# iqn_aid register map
Vendor: Texas Instruments
Registers are 32-bit, read-only, no defined reset value unless marked. A register's access mark holds for its fields unless they carry their own. Offsets are as the file gives them; [hi:lo] are bit positions; lines under a group give offsets from that group; {n}, {i} and the like mark numbered series; 'fields as' and 'values as' point back to an identical list.

## IQN_AID (part 2 of 2)
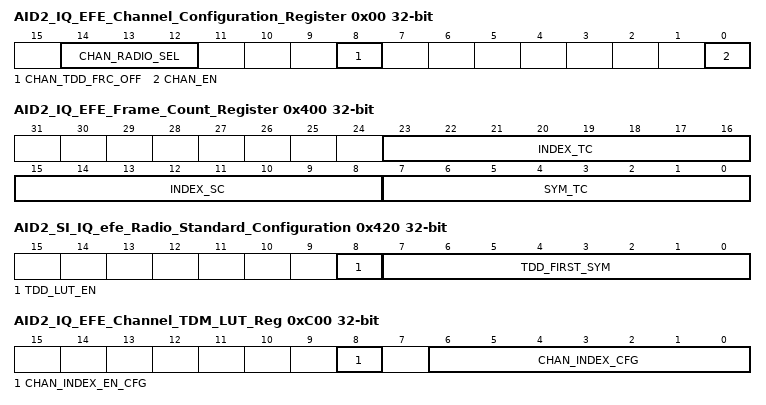
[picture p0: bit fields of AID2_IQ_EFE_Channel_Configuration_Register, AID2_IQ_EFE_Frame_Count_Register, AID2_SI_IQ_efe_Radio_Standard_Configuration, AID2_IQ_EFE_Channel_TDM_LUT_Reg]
0x00 AID2_IQ_EFE_Channel_Configuration_Register rw — (1 of 1, stride 0)
  [14:12] CHAN_RADIO_SEL — Assigns each channel to one of eight radio standard groups. i.e. radio standard 0 may be LTE 20MHz
  [8] CHAN_TDD_FRC_OFF — Alternate TDD mode for controlling TDD also used for GSM Base Band Hopping. APP SW controls updates this bit each symbol of time to control whether the next symbol will be TDD OFF. TDD OFF channels generate no Ingress DMA traffic and expect no Egress DMA
  [0] CHAN_EN — Enable channel
0x200 AID2_IQ_EFE_Configuration_Register rw — (1 of 1, stride 0)
  [0] LOOPBACK_EN — (TI use Only) 0x1: Ingress data from ICC is looped back to Egress data to ICC. DMA traffic is unused. (i.e. for purpose of early DFE only testing)
0x240 AID2_IQ_EFE_Global_Enable_Set_Reg wo — (1 of 1, stride 0)
  [31:0] DONT_CARE — A write of any value to this register which sets (enables) global enable
0x244 AID2_IQ_EFE_Global_Enable_Clear_Reg wo — (1 of 1, stride 0)
  [31:0] DONT_CARE — A write of any value to this register which clears (enables) global enable
0x248 AID2_IQ_EFE_Global_Enable_Status — (1 of 1, stride 0)
  [0] ENABLE — 0x1: efe_ON 0x0:efe_OFF
0x260 AID2_IQ_EFE_Channel_ON_Status_Reg — (1 of 1, stride 0)
  [31:0] CHAN_ON — 0x1: CHAN_ON 0x0:CHAN_OFF
0x280 AID2_IQ_EFE_IN_Packet_Status_Registers — (1 of 1, stride 0)
  [31:0] IN_PKT — 0x1: IN_PKT 0x0:OUT_PKT
0x2A0 AID2_IQ_EFE_DMA_SYNC_Status_Registers — (1 of 1, stride 0)
  [31:0] DMA_SYNC — 0x1: DMA synchronized to radio timing for this channel 0x0:DMA not synchronized to radio timing for this channel. Channel is in in re-sync mode.
0x400 AID2_IQ_EFE_Frame_Count_Register rw — (1 of 1, stride 0)
  [23:16] INDEX_TC — Radio Framing Counter. Index Counter Terminal Count. Index counter terminal count which is the last value of the Index Counter before it wraps. For simple use case, program same as frm_sym_tc.
  [15:8] INDEX_SC — Radio Framing Counter. Index Counter Starting Location. Starting location of the Sample Terminal Count LUT loaded into the Index Counter when it first starts and each time it wraps. Depending on the radio standard, the index will wrap once per radio frame
  [7:0] SYM_TC — Radio Framing Counter. Symbol Count. Number of symbols per frame programmed as a terminal count.
0x420 AID2_SI_IQ_efe_Radio_Standard_Configuration rw — (1 of 1, stride 0)
  [8] TDD_LUT_EN — Enable TDD
  [7:0] TDD_FIRST_SYM — Selects first symbol to start TDD
{0x440+0x20*i} AID2_IQ_efe_Radio_Standard_{i}_TDD_ENABLE_LUT rw (i=0..7) — (1 of 1, stride 0)
  [31:0] TDD_EN — enables/disables DMA of whole symbols (PktDMA packets). Program as 0xffff for most applications.
0x600 AID2_IQ_EFE_Channel_AXC_Offset_Reg rw — (1 of 32, stride 4)
  [19:0] AXC_OFFSET — AxC-by-AxC delay control. Allows different timing alignments for each AxC. DIO, AID applicactions this is a 4 sample offset relatvie to the group or TDM of AxC. AIL CPRI, this is a sample offset relative to the CPRI AxC Group. AIL OBSAI, this is a Radio
0x800 AID2_IQ_EFE_AxC_Framing_Sample_Terminal_Count rw — (1 of 256, stride 4)
  [17:0] SAMP_TC — Radio Framing Counter. Number of samples (4 Bytes) per radio symbol programmed as a terminal count
0xC00 AID2_IQ_EFE_Channel_TDM_LUT_Reg rw — (1 of 256, stride 4)
  [8] CHAN_INDEX_EN_CFG — TDM Channel Index LUT Enable
  [6:0] CHAN_INDEX_CFG — TDM Channel Index
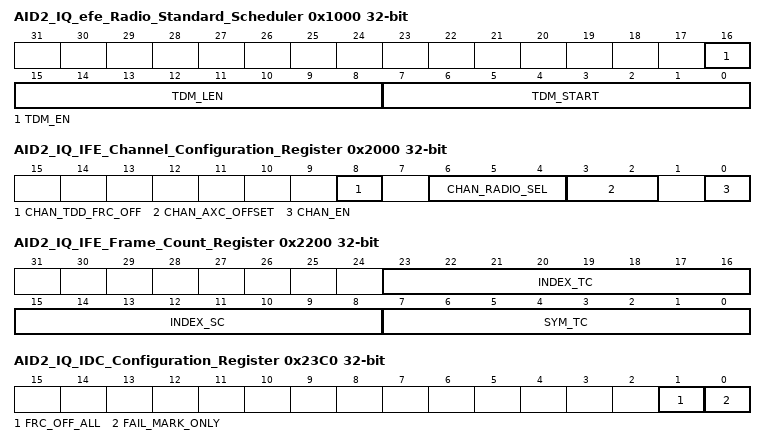
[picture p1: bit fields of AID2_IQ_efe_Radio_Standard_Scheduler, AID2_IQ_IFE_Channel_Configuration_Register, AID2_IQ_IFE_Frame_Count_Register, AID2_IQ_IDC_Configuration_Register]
0x1000 AID2_IQ_efe_Radio_Standard_Scheduler rw — (1 of 1, stride 0)
  [16] TDM_EN — EFE Scheculer Enable TDM
  [15:8] TDM_LEN — EFE Scheduler TDM Length
  [7:0] TDM_START — EFE Scheduler TDM Starting address in LUT
0x2000 AID2_IQ_IFE_Channel_Configuration_Register rw — (1 of 1, stride 0)
  [8] CHAN_TDD_FRC_OFF — Forces a channel into the TDD OFF state on the next symbol after it is set to a 1 regardless of the TDD configuration of the radio standard variant the channel is assigned to.
  [6:4] CHAN_RADIO_SEL — Radio Standard Select
  [3:2] CHAN_AXC_OFFSET — AxC Offset
  [0] CHAN_EN — Enable channel
0x2200 AID2_IQ_IFE_Frame_Count_Register rw — (1 of 1, stride 0)
  [23:16] INDEX_TC — Radio Framing Counter. Index Counter Terminal Count. Index counter terminal count which is the last value of the Index Counter before it wraps. For simple use case, program same as frm_sym_tc.
  [15:8] INDEX_SC — Radio Framing Counter. Index Counter Starting Location. Starting location of the Sample Terminal Count LUT loaded into the Index Counter when it first starts and each time it wraps.
  [7:0] SYM_TC — Radio Framing Counter. Symbol Count. Number of symbols per frame programmed as a terminal count.
0x2220 AID2_IQ_IFE_Radio_Standard_Configuration rw — (1 of 1, stride 0)
  [0] TDD_LUT_EN — Enable TDD
{0x2240+0x20*i} AID2_IQ_IFE_Radio_Standard_{i}_TDD_ENABLE_LUT rw (i=0..7) — (1 of 1, stride 0)
  fields as AID2_IQ_efe_Radio_Standard_0_TDD_ENABLE_LUT
0x2340 AID2_IQ_IFE_Global_Enable_Set_Reg wo — (1 of 1, stride 0)
  fields as AID2_IQ_EFE_Global_Enable_Set_Reg
0x2344 AID2_IQ_IFE_Global_Enable_Clear_Reg wo — (1 of 1, stride 0)
  fields as AID2_IQ_EFE_Global_Enable_Clear_Reg
0x2348 AID2_IQ_IFE_Global_Enable_Status — (1 of 1, stride 0)
  [0] ENABLE — 0x1: ife_ON 0x0:ife_OFF
0x2350 AID2_IQ_IFE_Channel_ON_Status_Reg — (1 of 1, stride 0)
  [31:0] CHAN_ON — 0x1: CHAN_ON 0x0:CHAN_OFF
0x2360 AID2_IQ_IFE_IN_Packet_Status_Registers — (1 of 1, stride 0)
  [31:0] IN_PKT — 0x1: IN_PKT 0x0:OUT_PKT
0x2384 AID2_IQ_IDC_Status_Register — (1 of 1, stride 0)
  [0] EMPTY — Empty indicator for both the PSI Staging FIFO and the CDC FIFO
0x2390 AID2_IQ_IDC_In_Packet_Status_Register — (1 of 1, stride 0)
  [31:0] INPKT — Per-channel in packet status bits where a 0 indicates that the channel is not actively processing a packet and a 1 indicates that it is actively processing a packet. The inpkt to channel assignment is such that inpkt\[0\] is associated with channel 0 and
0x23C0 AID2_IQ_IDC_Configuration_Register rw — (1 of 1, stride 0)
  [1] FRC_OFF_ALL — Forces off all Ingress channels without waiting for an end of symbol or time slot. All open packets are automatically closed by creating an EOP for each open packet
  [0] FAIL_MARK_ONLY — Controls how the IDC handles packet errors detected by IFE
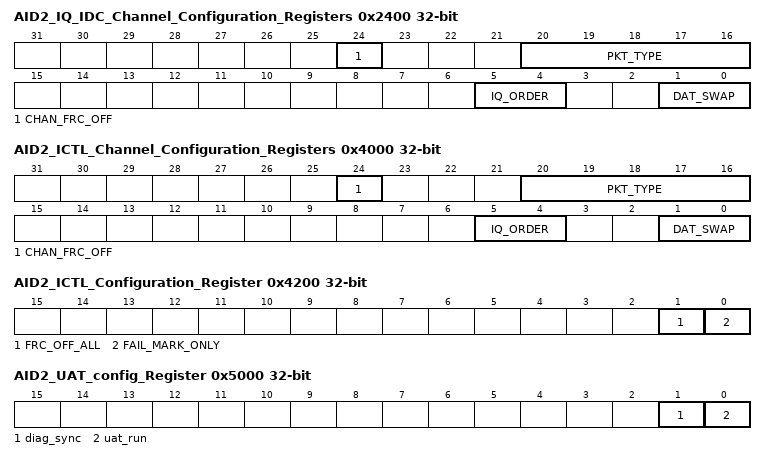
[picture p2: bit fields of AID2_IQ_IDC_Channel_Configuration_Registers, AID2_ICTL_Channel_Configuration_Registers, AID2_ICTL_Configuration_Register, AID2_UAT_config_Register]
0x2400 AID2_IQ_IDC_Channel_Configuration_Registers rw — (1 of 1, stride 0)
  [24] CHAN_FRC_OFF — Forces off all channel without waiting for an end of symbol or time slot. If channel has an open packet it is automatically closed by creating an EOP
  [20:16] PKT_TYPE — Programmable packet type that is inserted into pkt_type field of PKTDMA Info Word 0.
  [5:4] IQ_ORDER — IQ swapping control.
  [1:0] DAT_SWAP — Byte swapping control.
0x2800 AID2_IQ_IFE_AxC_Framing_Sample_Terminal_Count rw — (1 of 256, stride 4)
  fields as AID2_IQ_EFE_AxC_Framing_Sample_Terminal_Count
0x3000 AID2_ECTL_Global_Enable_Set_Reg wo — (1 of 1, stride 0)
  fields as AID2_IQ_EFE_Global_Enable_Set_Reg
0x3004 AID2_ECTL_Global_Enable_Clear_Reg wo — (1 of 1, stride 0)
  fields as AID2_IQ_EFE_Global_Enable_Clear_Reg
0x3008 AID2_ECTL_Global_Enable_Status — (1 of 1, stride 0)
  [0] ENABLE — 0x1: ectl_ON 0x0:ectl_OFF
0x3100 AID2_ECTL_Channel_ON_Status_Reg — (1 of 1, stride 0)
  [15:0] CHAN_ON — 0x1: CHAN_ON 0x0:CHAN_OFF
0x3140 AID2_ECTL_In_Packet_Status_Register — (1 of 1, stride 0)
  [15:0] IN_PKT — Per-channel in packet status bits where a 0 indicates that the channel is not actively processing a packet and a 1 indicates that it is actively processing a packet. The inpkt to channel assignment is such that inpkt\[0\] is associated with channel 0 and
0x3200 AID2_ECTL_Channel_Enable_Configuration_Register rw — (1 of 1, stride 0)
  [0] CHAN_EN — Enable channel
0x3400 AID2_ECTL_DB_Threshold_Register rw — (1 of 1, stride 0)
  [1:0] CHANNEL — Data Buffer Threshold before indicating data available. Per channel
0x4000 AID2_ICTL_Channel_Configuration_Registers rw — (1 of 1, stride 0)
  [24] CHAN_FRC_OFF — Forces off all channel without waiting for an EOP. If channel has an open packet it is automatically closed by creating an EOP
  [20:16] PKT_TYPE — Programmable packet type that is inserted into pkt_type field of PKTDMA Info Word 0.
  [5:4] IQ_ORDER — IQ swapping control.
  [1:0] DAT_SWAP — Byte swapping control.
0x4200 AID2_ICTL_Configuration_Register rw — (1 of 1, stride 0)
  [1] FRC_OFF_ALL — Forces off all Ingress channels without waiting for an EOP. All open packets are automatically closed by creating an EOP for each open packet
  [0] FAIL_MARK_ONLY — Controls how the ICTL handles packet errors detected by ICTL
0x4204 AID2_ICTL_Status_Register — (1 of 1, stride 0)
  fields as AID2_IQ_IDC_Status_Register
0x4210 AID2_ICTL_In_Packet_Status_Register — (1 of 1, stride 0)
  fields as AID2_ECTL_In_Packet_Status_Register
0x4280 AID2_ICTL_Global_Enable_Set_Reg wo — (1 of 1, stride 0)
  fields as AID2_IQ_EFE_Global_Enable_Set_Reg
0x4284 AID2_ICTL_Global_Enable_Clear_Reg wo — (1 of 1, stride 0)
  fields as AID2_IQ_EFE_Global_Enable_Clear_Reg
0x4288 AID2_ICTL_Global_Enable_Status — (1 of 1, stride 0)
  [0] ENABLE — 0x1: ictl_ON 0x0:ictl_OFF
0x42A0 AID2_ICTL_Channel_ON_Status_Reg — (1 of 1, stride 0)
  [15:0] CHAN_ON — 0x1: CHAN_ON 0x0:CHAN_OFF
0x4400 AID2_ICTL_Channel_Enable_Configuration_Register rw — (1 of 1, stride 0)
  [0] CHAN_EN — Enable channel
0x5000 AID2_UAT_config_Register rw — (1 of 1, stride 0)
  [1] diag_sync — diag_sync = 1 starts the BCN and RAD counters if uat_run is set and an AT sync is received. This is only used in simulation and for diagnostics
  [0] uat_run — UAT run starts the BCN and RAD counters free running
0x5004 AID2_UAT_BCN_terminal_count_Register rw — (1 of 1, stride 0)
  [24:0] val — UAT BCN terminal count. BCN counts from zero to this limit and wraps to zero. Program as 2,457,599 for sys_clk=245.76MHz and 3,071,999 for sys_clk=307.2MHz
0x5008 AID2_UAT_BCN_offset_Register rw — (1 of 1, stride 0)
  [24:0] val — Offset correction to the raw uAT BCN counter. Used to correct the alignment of the local uAT BCN to the master AT2 BCN. BCN is initially randomly started. SW uses uat_sync_bcn_capture_sts rd_val to calculate offset correction factor. This correction
0x500C AID2_UAT_SYNC_BCN_capture_Register — (1 of 1, stride 0)
  [24:0] rd_val — uAT raw BCN value captured each frame boundary of AT2 master BCN. Used to calculate uAT BCN offset value for the purpose of aligning uAT to AT2 BCN.
0x5080 AID2_UAT_RADT_terminal_count_Register rw — (1 of 8, stride 16)
  [24:0] val — UAT RADT terminal count. (i.e. 2,457,599 for WCDMA with sys_clk=245.76MHz)
0x5084 AID2_UAT_RADT_offset_Register rw — (1 of 8, stride 16)
  [24:0] val — UAT RADT offset. Value which is added to the raw RADT as a timing correction. RadT is initially randomly started, SW uses radt_capture value to calculate offset correction factor. This correction factor will be Frame size
0x5088 AID2_UAT_SYNC_RADT_capture_Register — (1 of 8, stride 16)
  [24:0] rd_val — UAT RADT sync capture captures the offset RADT count when a uat_mst_slv_sync from the AT occurs. Used by SW to determine correct RADT offset to apply.
0x5100 AID2_UAT_RADT_terminal_count_Register rw — (1 of 8, stride 16)
  fields as AID2_UAT_RADT_terminal_count_Register
0x5104 AID2_UAT_RADT_offset_Register rw — (1 of 8, stride 16)
  fields as AID2_UAT_RADT_offset_Register
0x5108 AID2_UAT_SYNC_RADT_capture_Register — (1 of 8, stride 16)
  fields as AID2_UAT_SYNC_RADT_capture_Register
0x5200 AID2_UAT_RADT_event_compare_Register rw — (1 of 22, stride 8)
  [24:0] val — UAT RADT event compare per RADT. When compare value equals RADT count, frame rate event is generated. Also periodic event (i.e. 4SAMP) is started. The 0 to 7 are for si egress, 8 to 15 for si ingress, 16 to 18 for dio egress, 19 to 21 for dio ingress
0x5204 AID2_UAT_RADT_event_clock_count_tc_Register rw — (1 of 22, stride 8)
  [15:0] val — UAT RADT event clock counter terminal count controls spacing of the periodic strobe (i.e. 4SAMP). Once the uat_evt_radt_cmp_cfg equals the RADT, the period strobe will fire and re-fire every time a clock counter reaches this terminal count. The The 0 to 7
0x8000 AID2_IQ_EDC_Configuration_Register rw — (1 of 1, stride 0)
  [0] PSI_ERR_CHK_DISABLE — Controls how the EDC handles packet errors detected by efe
0x8004 AID2_IQ_EDC_SOP_Counter_Status_Register — (1 of 1, stride 0)
  [23:0] SOP_CNT — Count of the number of SOPs seen by the IQ EDC
0x8008 AID2_IQ_EDC_EOP_Counter_Status_Register — (1 of 1, stride 0)
  [23:0] EOP_CNT — Count of the number of EOPs seen by the IQ EDC
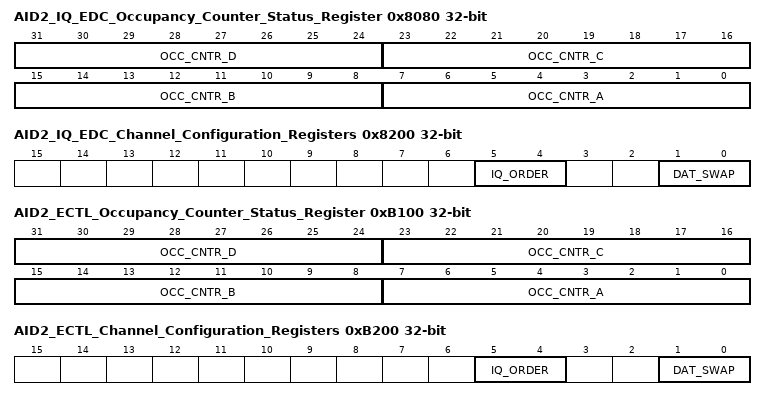
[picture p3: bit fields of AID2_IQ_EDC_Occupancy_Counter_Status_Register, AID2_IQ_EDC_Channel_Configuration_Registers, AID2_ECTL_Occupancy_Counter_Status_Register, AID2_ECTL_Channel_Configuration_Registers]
0x8080 AID2_IQ_EDC_Occupancy_Counter_Status_Register — (1 of 1, stride 0)
  [31:24] OCC_CNTR_D — Occupancy Counter for register D for this address
  [23:16] OCC_CNTR_C — Occupancy Counter for register C for this address
  [15:8] OCC_CNTR_B — Occupancy Counter for register B for this address
  [7:0] OCC_CNTR_A — Occupancy Counter for register A for this address
0x8200 AID2_IQ_EDC_Channel_Configuration_Registers rw — (1 of 1, stride 0)
  [5:4] IQ_ORDER — IQ swapping control.
  [1:0] DAT_SWAP — Byte swapping control.
0xA000 AID2_IQ_IDC_Rate_Control_Configuration_Register rw — (1 of 1, stride 0)
  [3:0] RATE — Rate Controller will allow the IDC to create RATE+1 active requests on the PSI bus within a 32 clock cycle window. As an example, a value of 7 will allow the IDC to create 8 active requests within a 32-clock cycle window which uses 25% of the PSI bus.
0xA004 AID2_IQ_IDC_SOP_Counter_Register — (1 of 1, stride 0)
  [23:0] SOP_CNT — Wrapping count of SOPs sent on PSI.
0xA008 AID2_IQ_IDC_EOP_Counter_Register — (1 of 1, stride 0)
  [23:0] EOP_CNT — Wrapping count of EOPs sent on PSI.
0xB000 AID2_ECTL_Rate_Control_Configuration_Register rw — (1 of 1, stride 0)
  [3:0] RATE — Rate Controller will allow the ECTL to create RATE+1 active requests on the PSI bus within a 16 clock cycle window. As an example, a value of 7 will allow the ICTL to create 8 active requests within a 16-clock cycle window which uses 50% of the PSI bus.
0xB004 AID2_ECTL_SOP_Counter_Status_Register — (1 of 1, stride 0)
  [23:0] SOP_CNT — Count of the number of SOPs seen by the ECTL
0xB008 AID2_ECTL_EOP_Counter_Status_Register — (1 of 1, stride 0)
  [23:0] EOP_CNT — Count of the number of EOPs seen by the ECTL
0xB100 AID2_ECTL_Occupancy_Counter_Status_Register — (1 of 1, stride 0)
  fields as AID2_IQ_EDC_Occupancy_Counter_Status_Register
0xB200 AID2_ECTL_Channel_Configuration_Registers rw — (1 of 1, stride 0)
  fields as AID2_IQ_EDC_Channel_Configuration_Registers
0xC000 AID2_ICTL_Rate_Control_Configuration_Register rw — (1 of 1, stride 0)
  [3:0] RATE — Rate Controller will allow the ICTL to create RATE+1 active requests on the PSI bus within a 16 clock cycle window. As an example, a value of 7 will allow the ICTL to create 8 active requests within a 16-clock cycle window which uses 50% of the PSI bus.
0xC004 AID2_ICTL_SOP_Counter_Register — (1 of 1, stride 0)
  [23:0] SOP_CNT — Wrapping count of SOPs sent on PSI.
0xC008 AID2_ICTL_EOP_Counter_Register — (1 of 1, stride 0)
  [23:0] EOP_CNT — Wrapping count of EOPs sent on PSI.
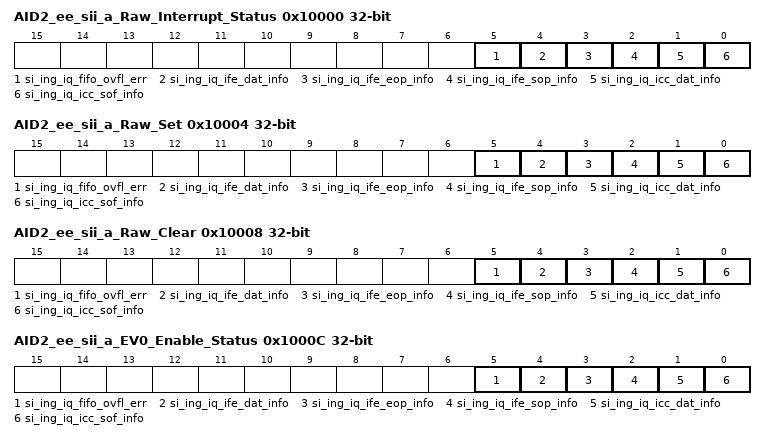
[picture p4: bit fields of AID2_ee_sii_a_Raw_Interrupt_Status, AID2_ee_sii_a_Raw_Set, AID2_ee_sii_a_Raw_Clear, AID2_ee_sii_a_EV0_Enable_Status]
0x10000 AID2_ee_sii_a_Raw_Interrupt_Status — (1 of 1, stride 0)
  [5] si_ing_iq_fifo_ovfl_err — SI Ingress IQ FIFO overflow error
  [4] si_ing_iq_ife_dat_info — SI Ingress IQ IFE transmitted valid data phase
  [3] si_ing_iq_ife_eop_info — SI Ingress IQ IFE transmitted EOP
  [2] si_ing_iq_ife_sop_info — SI Ingress IQ IFE transmitted SOP
  [1] si_ing_iq_icc_dat_info — SI Ingress IQ ICC data transfer received
  [0] si_ing_iq_icc_sof_info — SI Ingress IQ ICC Start of Frame received
0x10004 AID2_ee_sii_a_Raw_Set wo — (1 of 1, stride 0)
  [5] si_ing_iq_fifo_ovfl_err — Sets the corresponding bit in the raw_status register when set. Write only, self-clears.
  [4] si_ing_iq_ife_dat_info — Sets the corresponding bit in the raw_status register when set. Write only, self-clears.
  [3] si_ing_iq_ife_eop_info — Sets the corresponding bit in the raw_status register when set. Write only, self-clears.
  [2] si_ing_iq_ife_sop_info — Sets the corresponding bit in the raw_status register when set. Write only, self-clears.
  [1] si_ing_iq_icc_dat_info — Sets the corresponding bit in the raw_status register when set. Write only, self-clears.
  [0] si_ing_iq_icc_sof_info — Sets the corresponding bit in the raw_status register when set. Write only, self-clears.
0x10008 AID2_ee_sii_a_Raw_Clear wo — (1 of 1, stride 0)
  [5] si_ing_iq_fifo_ovfl_err — Clears the corresponding bit in the raw_status register when set. Write only, self-clears.
  [4] si_ing_iq_ife_dat_info — Clears the corresponding bit in the raw_status register when set. Write only, self-clears.
  [3] si_ing_iq_ife_eop_info — Clears the corresponding bit in the raw_status register when set. Write only, self-clears.
  [2] si_ing_iq_ife_sop_info — Clears the corresponding bit in the raw_status register when set. Write only, self-clears.
  [1] si_ing_iq_icc_dat_info — Clears the corresponding bit in the raw_status register when set. Write only, self-clears.
  [0] si_ing_iq_icc_sof_info — Clears the corresponding bit in the raw_status register when set. Write only, self-clears.
0x1000C AID2_ee_sii_a_EV0_Enable_Status — (1 of 1, stride 0)
  [5] si_ing_iq_fifo_ovfl_err — When set allows the corresponding bit in the raw_status register to generate the intr_sts interrupt. Read only.
  [4] si_ing_iq_ife_dat_info — When set allows the corresponding bit in the raw_status register to generate the intr_sts interrupt. Read only.
  [3] si_ing_iq_ife_eop_info — When set allows the corresponding bit in the raw_status register to generate the intr_sts interrupt. Read only.
  [2] si_ing_iq_ife_sop_info — When set allows the corresponding bit in the raw_status register to generate the intr_sts interrupt. Read only.
  [1] si_ing_iq_icc_dat_info — When set allows the corresponding bit in the raw_status register to generate the intr_sts interrupt. Read only.
  [0] si_ing_iq_icc_sof_info — When set allows the corresponding bit in the raw_status register to generate the intr_sts interrupt. Read only.
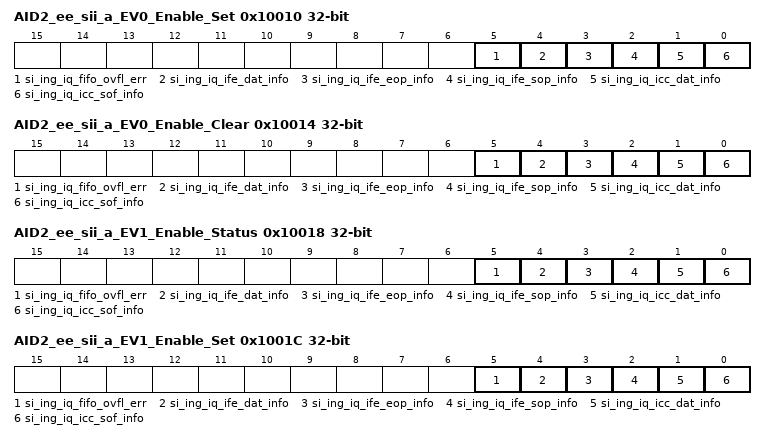
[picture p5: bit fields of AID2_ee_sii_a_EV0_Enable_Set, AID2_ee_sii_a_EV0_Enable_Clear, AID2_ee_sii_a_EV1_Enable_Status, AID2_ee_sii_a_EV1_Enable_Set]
0x10010 AID2_ee_sii_a_EV0_Enable_Set wo — (1 of 1, stride 0)
  [5] si_ing_iq_fifo_ovfl_err — Sets the corresponding bit in the enable register when set. Write only, self-clears.
  [4] si_ing_iq_ife_dat_info — Sets the corresponding bit in the enable register when set. Write only, self-clears.
  [3] si_ing_iq_ife_eop_info — Sets the corresponding bit in the enable register when set. Write only, self-clears.
  [2] si_ing_iq_ife_sop_info — Sets the corresponding bit in the enable register when set. Write only, self-clears.
  [1] si_ing_iq_icc_dat_info — Sets the corresponding bit in the enable register when set. Write only, self-clears.
  [0] si_ing_iq_icc_sof_info — Sets the corresponding bit in the enable register when set. Write only, self-clears.
0x10014 AID2_ee_sii_a_EV0_Enable_Clear wo — (1 of 1, stride 0)
  [5] si_ing_iq_fifo_ovfl_err — Clears the corresponding bit in the enable register when set. Write only, self-clears.
  [4] si_ing_iq_ife_dat_info — Clears the corresponding bit in the enable register when set. Write only, self-clears.
  [3] si_ing_iq_ife_eop_info — Clears the corresponding bit in the enable register when set. Write only, self-clears.
  [2] si_ing_iq_ife_sop_info — Clears the corresponding bit in the enable register when set. Write only, self-clears.
  [1] si_ing_iq_icc_dat_info — Clears the corresponding bit in the enable register when set. Write only, self-clears.
  [0] si_ing_iq_icc_sof_info — Clears the corresponding bit in the enable register when set. Write only, self-clears.
0x10018 AID2_ee_sii_a_EV1_Enable_Status — (1 of 1, stride 0)
  [5] si_ing_iq_fifo_ovfl_err — When set allows the corresponding bit in the raw_status register to generate the intr1_sts interrupt. Read only.
  [4] si_ing_iq_ife_dat_info — When set allows the corresponding bit in the raw_status register to generate the intr1_sts interrupt. Read only.
  [3] si_ing_iq_ife_eop_info — When set allows the corresponding bit in the raw_status register to generate the intr1_sts interrupt. Read only.
  [2] si_ing_iq_ife_sop_info — When set allows the corresponding bit in the raw_status register to generate the intr1_sts interrupt. Read only.
  [1] si_ing_iq_icc_dat_info — When set allows the corresponding bit in the raw_status register to generate the intr1_sts interrupt. Read only.
  [0] si_ing_iq_icc_sof_info — When set allows the corresponding bit in the raw_status register to generate the intr1_sts interrupt. Read only.
0x1001C AID2_ee_sii_a_EV1_Enable_Set wo — (1 of 1, stride 0)
  [5] si_ing_iq_fifo_ovfl_err — Sets the corresponding bit in the intr1_status register when set. Write only, self-clears.
  [4] si_ing_iq_ife_dat_info — Sets the corresponding bit in the intr1_status register when set. Write only, self-clears.
  [3] si_ing_iq_ife_eop_info — Sets the corresponding bit in the intr1_status register when set. Write only, self-clears.
  [2] si_ing_iq_ife_sop_info — Sets the corresponding bit in the intr1_status register when set. Write only, self-clears.
  [1] si_ing_iq_icc_dat_info — Sets the corresponding bit in the intr1_status register when set. Write only, self-clears.
  [0] si_ing_iq_icc_sof_info — Sets the corresponding bit in the intr1_status register when set. Write only, self-clears.
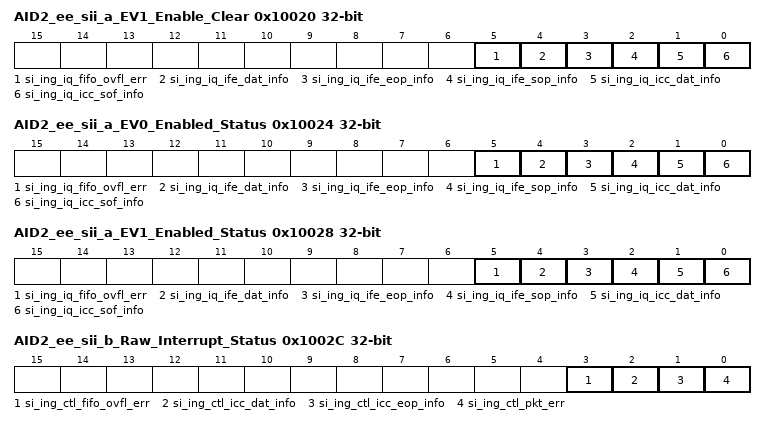
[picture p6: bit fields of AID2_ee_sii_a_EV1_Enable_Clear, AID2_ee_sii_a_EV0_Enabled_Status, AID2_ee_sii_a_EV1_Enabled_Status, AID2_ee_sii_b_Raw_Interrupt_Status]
0x10020 AID2_ee_sii_a_EV1_Enable_Clear wo — (1 of 1, stride 0)
  [5] si_ing_iq_fifo_ovfl_err — Clears the corresponding bit in the intr1_status register when set. Write only, self-clears.
  [4] si_ing_iq_ife_dat_info — Clears the corresponding bit in the intr1_status register when set. Write only, self-clears.
  [3] si_ing_iq_ife_eop_info — Clears the corresponding bit in the intr1_status register when set. Write only, self-clears.
  [2] si_ing_iq_ife_sop_info — Clears the corresponding bit in the intr1_status register when set. Write only, self-clears.
  [1] si_ing_iq_icc_dat_info — Clears the corresponding bit in the intr1_status register when set. Write only, self-clears.
  [0] si_ing_iq_icc_sof_info — Clears the corresponding bit in the intr1_status register when set. Write only, self-clears.
0x10024 AID2_ee_sii_a_EV0_Enabled_Status — (1 of 1, stride 0)
  [5] si_ing_iq_fifo_ovfl_err — AND-ed raw_status bits with the corresponding bit in the enable_status register. Read only.
  [4] si_ing_iq_ife_dat_info — AND-ed raw_status bits with the corresponding bit in the enable_status register. Read only.
  [3] si_ing_iq_ife_eop_info — AND-ed raw_status bits with the corresponding bit in the enable_status register. Read only.
  [2] si_ing_iq_ife_sop_info — AND-ed raw_status bits with the corresponding bit in the enable_status register. Read only.
  [1] si_ing_iq_icc_dat_info — AND-ed raw_status bits with the corresponding bit in the enable_status register. Read only.
  [0] si_ing_iq_icc_sof_info — AND-ed raw_status bits with the corresponding bit in the enable_status register. Read only.
0x10028 AID2_ee_sii_a_EV1_Enabled_Status — (1 of 1, stride 0)
  [5] si_ing_iq_fifo_ovfl_err — AND-ed raw_status bits with the corresponding bit in the intr1_status register. Read only.
  [4] si_ing_iq_ife_dat_info — AND-ed raw_status bits with the corresponding bit in the intr1_status register. Read only.
  [3] si_ing_iq_ife_eop_info — AND-ed raw_status bits with the corresponding bit in the intr1_status register. Read only.
  [2] si_ing_iq_ife_sop_info — AND-ed raw_status bits with the corresponding bit in the intr1_status register. Read only.
  [1] si_ing_iq_icc_dat_info — AND-ed raw_status bits with the corresponding bit in the intr1_status register. Read only.
  [0] si_ing_iq_icc_sof_info — AND-ed raw_status bits with the corresponding bit in the intr1_status register. Read only.
0x1002C AID2_ee_sii_b_Raw_Interrupt_Status — (1 of 1, stride 0)
  [3] si_ing_ctl_fifo_ovfl_err — SI Ingress CTL FIFO overflow error
  [2] si_ing_ctl_icc_dat_info — SI Ingress CTL received valid data phase from ICC
  [1] si_ing_ctl_icc_eop_info — SI Ingress CTL received EOP from ICC
  [0] si_ing_ctl_pkt_err — SI Ingress CTL Packet error occurred
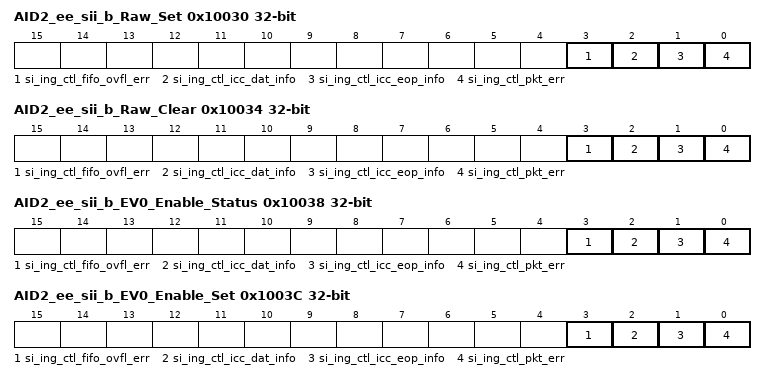
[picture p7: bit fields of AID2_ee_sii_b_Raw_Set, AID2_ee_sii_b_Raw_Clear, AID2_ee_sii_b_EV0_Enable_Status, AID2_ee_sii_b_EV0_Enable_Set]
0x10030 AID2_ee_sii_b_Raw_Set wo — (1 of 1, stride 0)
  [3] si_ing_ctl_fifo_ovfl_err — Sets the corresponding bit in the raw_status register when set. Write only, self-clears.
  [2] si_ing_ctl_icc_dat_info — Sets the corresponding bit in the raw_status register when set. Write only, self-clears.
  [1] si_ing_ctl_icc_eop_info — Sets the corresponding bit in the raw_status register when set. Write only, self-clears.
  [0] si_ing_ctl_pkt_err — Sets the corresponding bit in the raw_status register when set. Write only, self-clears.
0x10034 AID2_ee_sii_b_Raw_Clear wo — (1 of 1, stride 0)
  [3] si_ing_ctl_fifo_ovfl_err — Clears the corresponding bit in the raw_status register when set. Write only, self-clears.
  [2] si_ing_ctl_icc_dat_info — Clears the corresponding bit in the raw_status register when set. Write only, self-clears.
  [1] si_ing_ctl_icc_eop_info — Clears the corresponding bit in the raw_status register when set. Write only, self-clears.
  [0] si_ing_ctl_pkt_err — Clears the corresponding bit in the raw_status register when set. Write only, self-clears.
0x10038 AID2_ee_sii_b_EV0_Enable_Status — (1 of 1, stride 0)
  [3] si_ing_ctl_fifo_ovfl_err — When set allows the corresponding bit in the raw_status register to generate the intr_sts interrupt. Read only.
  [2] si_ing_ctl_icc_dat_info — When set allows the corresponding bit in the raw_status register to generate the intr_sts interrupt. Read only.
  [1] si_ing_ctl_icc_eop_info — When set allows the corresponding bit in the raw_status register to generate the intr_sts interrupt. Read only.
  [0] si_ing_ctl_pkt_err — When set allows the corresponding bit in the raw_status register to generate the intr_sts interrupt. Read only.
0x1003C AID2_ee_sii_b_EV0_Enable_Set wo — (1 of 1, stride 0)
  [3] si_ing_ctl_fifo_ovfl_err — Sets the corresponding bit in the enable register when set. Write only, self-clears.
  [2] si_ing_ctl_icc_dat_info — Sets the corresponding bit in the enable register when set. Write only, self-clears.
  [1] si_ing_ctl_icc_eop_info — Sets the corresponding bit in the enable register when set. Write only, self-clears.
  [0] si_ing_ctl_pkt_err — Sets the corresponding bit in the enable register when set. Write only, self-clears.
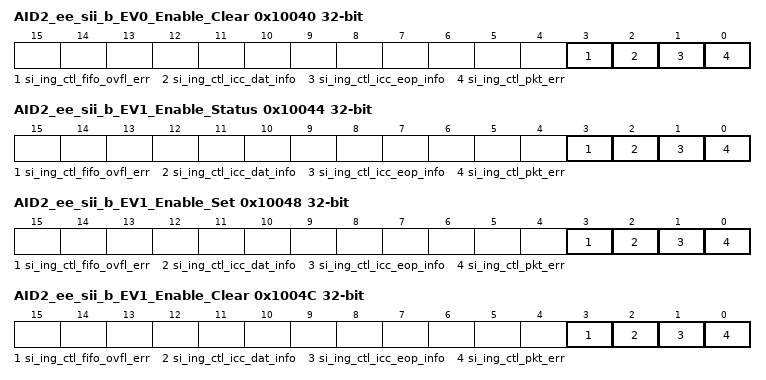
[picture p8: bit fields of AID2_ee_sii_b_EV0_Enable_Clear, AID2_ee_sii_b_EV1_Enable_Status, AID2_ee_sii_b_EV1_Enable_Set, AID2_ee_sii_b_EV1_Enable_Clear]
0x10040 AID2_ee_sii_b_EV0_Enable_Clear wo — (1 of 1, stride 0)
  [3] si_ing_ctl_fifo_ovfl_err — Clears the corresponding bit in the enable register when set. Write only, self-clears.
  [2] si_ing_ctl_icc_dat_info — Clears the corresponding bit in the enable register when set. Write only, self-clears.
  [1] si_ing_ctl_icc_eop_info — Clears the corresponding bit in the enable register when set. Write only, self-clears.
  [0] si_ing_ctl_pkt_err — Clears the corresponding bit in the enable register when set. Write only, self-clears.
0x10044 AID2_ee_sii_b_EV1_Enable_Status — (1 of 1, stride 0)
  [3] si_ing_ctl_fifo_ovfl_err — When set allows the corresponding bit in the raw_status register to generate the intr1_sts interrupt. Read only.
  [2] si_ing_ctl_icc_dat_info — When set allows the corresponding bit in the raw_status register to generate the intr1_sts interrupt. Read only.
  [1] si_ing_ctl_icc_eop_info — When set allows the corresponding bit in the raw_status register to generate the intr1_sts interrupt. Read only.
  [0] si_ing_ctl_pkt_err — When set allows the corresponding bit in the raw_status register to generate the intr1_sts interrupt. Read only.
0x10048 AID2_ee_sii_b_EV1_Enable_Set wo — (1 of 1, stride 0)
  [3] si_ing_ctl_fifo_ovfl_err — Sets the corresponding bit in the intr1_status register when set. Write only, self-clears.
  [2] si_ing_ctl_icc_dat_info — Sets the corresponding bit in the intr1_status register when set. Write only, self-clears.
  [1] si_ing_ctl_icc_eop_info — Sets the corresponding bit in the intr1_status register when set. Write only, self-clears.
  [0] si_ing_ctl_pkt_err — Sets the corresponding bit in the intr1_status register when set. Write only, self-clears.
0x1004C AID2_ee_sii_b_EV1_Enable_Clear wo — (1 of 1, stride 0)
  [3] si_ing_ctl_fifo_ovfl_err — Clears the corresponding bit in the intr1_status register when set. Write only, self-clears.
  [2] si_ing_ctl_icc_dat_info — Clears the corresponding bit in the intr1_status register when set. Write only, self-clears.
  [1] si_ing_ctl_icc_eop_info — Clears the corresponding bit in the intr1_status register when set. Write only, self-clears.
  [0] si_ing_ctl_pkt_err — Clears the corresponding bit in the intr1_status register when set. Write only, self-clears.
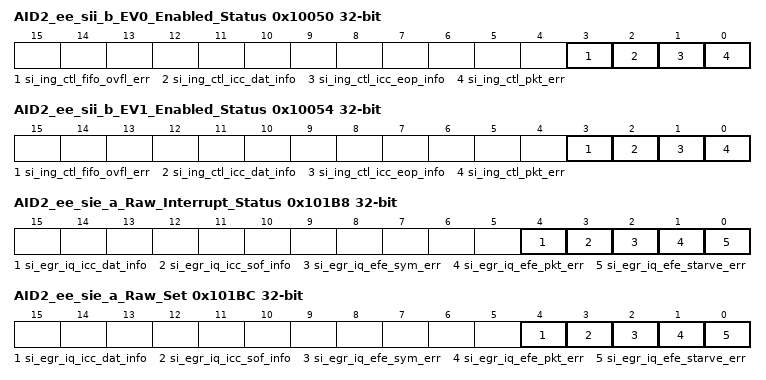
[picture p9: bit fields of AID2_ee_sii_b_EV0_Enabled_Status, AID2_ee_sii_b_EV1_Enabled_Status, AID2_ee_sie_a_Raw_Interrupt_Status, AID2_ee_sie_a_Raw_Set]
0x10050 AID2_ee_sii_b_EV0_Enabled_Status — (1 of 1, stride 0)
  [3] si_ing_ctl_fifo_ovfl_err — AND-ed raw_status bits with the corresponding bit in the enable_status register. Read only.
  [2] si_ing_ctl_icc_dat_info — AND-ed raw_status bits with the corresponding bit in the enable_status register. Read only.
  [1] si_ing_ctl_icc_eop_info — AND-ed raw_status bits with the corresponding bit in the enable_status register. Read only.
  [0] si_ing_ctl_pkt_err — AND-ed raw_status bits with the corresponding bit in the enable_status register. Read only.
0x10054 AID2_ee_sii_b_EV1_Enabled_Status — (1 of 1, stride 0)
  [3] si_ing_ctl_fifo_ovfl_err — AND-ed raw_status bits with the corresponding bit in the intr1_status register. Read only.
  [2] si_ing_ctl_icc_dat_info — AND-ed raw_status bits with the corresponding bit in the intr1_status register. Read only.
  [1] si_ing_ctl_icc_eop_info — AND-ed raw_status bits with the corresponding bit in the intr1_status register. Read only.
  [0] si_ing_ctl_pkt_err — AND-ed raw_status bits with the corresponding bit in the intr1_status register. Read only.
0x10058 AID2_ee_sii_c_Raw_Interrupt_Status — (1 of 1, stride 0)
  [31:0] si_ing_iq_sof_err — SI Ingress IQ per channel Start of Frame alignment error
0x1005C AID2_ee_sii_c_Raw_Set wo — (1 of 1, stride 0)
  [31:0] si_ing_iq_sof_err — Sets the corresponding bit in the raw_status register when set. Write only, self-clears.
0x10060 AID2_ee_sii_c_Raw_Clear wo — (1 of 1, stride 0)
  [31:0] si_ing_iq_sof_err — Clears the corresponding bit in the raw_status register when set. Write only, self-clears.
0x10064 AID2_ee_sii_c_EV0_Enable_Status — (1 of 1, stride 0)
  [31:0] si_ing_iq_sof_err — When set allows the corresponding bit in the raw_status register to generate the intr_sts interrupt. Read only.
0x10068 AID2_ee_sii_c_EV0_Enable_Set wo — (1 of 1, stride 0)
  [31:0] si_ing_iq_sof_err — Sets the corresponding bit in the enable register when set. Write only, self-clears.
0x1006C AID2_ee_sii_c_EV0_Enable_Clear wo — (1 of 1, stride 0)
  [31:0] si_ing_iq_sof_err — Clears the corresponding bit in the enable register when set. Write only, self-clears.
0x10070 AID2_ee_sii_c_EV1_Enable_Status — (1 of 1, stride 0)
  [31:0] si_ing_iq_sof_err — When set allows the corresponding bit in the raw_status register to generate the intr1_sts interrupt. Read only.
0x10074 AID2_ee_sii_c_EV1_Enable_Set wo — (1 of 1, stride 0)
  [31:0] si_ing_iq_sof_err — Sets the corresponding bit in the intr1_status register when set. Write only, self-clears.
0x10078 AID2_ee_sii_c_EV1_Enable_Clear wo — (1 of 1, stride 0)
  [31:0] si_ing_iq_sof_err — Clears the corresponding bit in the intr1_status register when set. Write only, self-clears.
0x1007C AID2_ee_sii_c_EV0_Enabled_Status — (1 of 1, stride 0)
  [31:0] si_ing_iq_sof_err — AND-ed raw_status bits with the corresponding bit in the enable_status register. Read only.
0x10080 AID2_ee_sii_c_EV1_Enabled_Status — (1 of 1, stride 0)
  [31:0] si_ing_iq_sof_err — AND-ed raw_status bits with the corresponding bit in the intr1_status register. Read only.
0x10108 AID2_ee_sii_d_Raw_Interrupt_Status — (1 of 1, stride 0)
  [15:0] si_ing_ctl_icc_sop_info — SI Ingress CTL per channel SOP received from ICC
0x1010C AID2_ee_sii_d_Raw_Set wo — (1 of 1, stride 0)
  [15:0] si_ing_ctl_icc_sop_info — Sets the corresponding bit in the raw_status register when set. Write only, self-clears.
0x10110 AID2_ee_sii_d_Raw_Clear wo — (1 of 1, stride 0)
  [15:0] si_ing_ctl_icc_sop_info — Clears the corresponding bit in the raw_status register when set. Write only, self-clears.
0x10114 AID2_ee_sii_d_EV0_Enable_Status — (1 of 1, stride 0)
  [15:0] si_ing_ctl_icc_sop_info — When set allows the corresponding bit in the raw_status register to generate the intr_sts interrupt. Read only.
0x10118 AID2_ee_sii_d_EV0_Enable_Set wo — (1 of 1, stride 0)
  [15:0] si_ing_ctl_icc_sop_info — Sets the corresponding bit in the enable register when set. Write only, self-clears.
0x1011C AID2_ee_sii_d_EV0_Enable_Clear wo — (1 of 1, stride 0)
  [15:0] si_ing_ctl_icc_sop_info — Clears the corresponding bit in the enable register when set. Write only, self-clears.
0x10120 AID2_ee_sii_d_EV1_Enable_Status — (1 of 1, stride 0)
  [15:0] si_ing_ctl_icc_sop_info — When set allows the corresponding bit in the raw_status register to generate the intr1_sts interrupt. Read only.
0x10124 AID2_ee_sii_d_EV1_Enable_Set wo — (1 of 1, stride 0)
  [15:0] si_ing_ctl_icc_sop_info — Sets the corresponding bit in the intr1_status register when set. Write only, self-clears.
0x10128 AID2_ee_sii_d_EV1_Enable_Clear wo — (1 of 1, stride 0)
  [15:0] si_ing_ctl_icc_sop_info — Clears the corresponding bit in the intr1_status register when set. Write only, self-clears.
0x1012C AID2_ee_sii_d_EV0_Enabled_Status — (1 of 1, stride 0)
  [15:0] si_ing_ctl_icc_sop_info — AND-ed raw_status bits with the corresponding bit in the enable_status register. Read only.
0x10130 AID2_ee_sii_d_EV1_Enabled_Status — (1 of 1, stride 0)
  [15:0] si_ing_ctl_icc_sop_info — AND-ed raw_status bits with the corresponding bit in the intr1_status register. Read only.
0x101B8 AID2_ee_sie_a_Raw_Interrupt_Status — (1 of 1, stride 0)
  [4] si_egr_iq_icc_dat_info — SI Egress IQ transmitted data to ICC
  [3] si_egr_iq_icc_sof_info — SI Egress IQ transmitted Start of Frame to ICC
  [2] si_egr_iq_efe_sym_err — SI Egress IQ EFE symbol number error. (Packet boundary errors due to a missing, early, or late SOP disable the reporting of any symbol errors since the symbol number is only valid for SOPs)
  [1] si_egr_iq_efe_pkt_err — SI Egress IQ EFE packet boundary error
  [0] si_egr_iq_efe_starve_err — SI Egress IQ EFE data starvation error
0x101BC AID2_ee_sie_a_Raw_Set wo — (1 of 1, stride 0)
  [4] si_egr_iq_icc_dat_info — Sets the corresponding bit in the raw_status register when set. Write only, self-clears.
  [3] si_egr_iq_icc_sof_info — Sets the corresponding bit in the raw_status register when set. Write only, self-clears.
  [2] si_egr_iq_efe_sym_err — Sets the corresponding bit in the raw_status register when set. Write only, self-clears.
  [1] si_egr_iq_efe_pkt_err — Sets the corresponding bit in the raw_status register when set. Write only, self-clears.
  [0] si_egr_iq_efe_starve_err — Sets the corresponding bit in the raw_status register when set. Write only, self-clears.
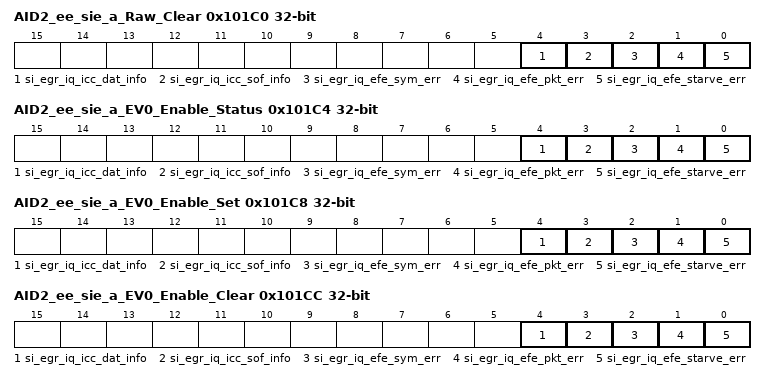
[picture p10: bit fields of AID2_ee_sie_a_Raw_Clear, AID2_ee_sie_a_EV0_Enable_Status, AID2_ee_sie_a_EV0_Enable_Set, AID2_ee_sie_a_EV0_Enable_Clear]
0x101C0 AID2_ee_sie_a_Raw_Clear wo — (1 of 1, stride 0)
  [4] si_egr_iq_icc_dat_info — Clears the corresponding bit in the raw_status register when set. Write only, self-clears.
  [3] si_egr_iq_icc_sof_info — Clears the corresponding bit in the raw_status register when set. Write only, self-clears.
  [2] si_egr_iq_efe_sym_err — Clears the corresponding bit in the raw_status register when set. Write only, self-clears.
  [1] si_egr_iq_efe_pkt_err — Clears the corresponding bit in the raw_status register when set. Write only, self-clears.
  [0] si_egr_iq_efe_starve_err — Clears the corresponding bit in the raw_status register when set. Write only, self-clears.
0x101C4 AID2_ee_sie_a_EV0_Enable_Status — (1 of 1, stride 0)
  [4] si_egr_iq_icc_dat_info — When set allows the corresponding bit in the raw_status register to generate the intr_sts interrupt. Read only.
  [3] si_egr_iq_icc_sof_info — When set allows the corresponding bit in the raw_status register to generate the intr_sts interrupt. Read only.
  [2] si_egr_iq_efe_sym_err — When set allows the corresponding bit in the raw_status register to generate the intr_sts interrupt. Read only.
  [1] si_egr_iq_efe_pkt_err — When set allows the corresponding bit in the raw_status register to generate the intr_sts interrupt. Read only.
  [0] si_egr_iq_efe_starve_err — When set allows the corresponding bit in the raw_status register to generate the intr_sts interrupt. Read only.
0x101C8 AID2_ee_sie_a_EV0_Enable_Set wo — (1 of 1, stride 0)
  [4] si_egr_iq_icc_dat_info — Sets the corresponding bit in the enable register when set. Write only, self-clears.
  [3] si_egr_iq_icc_sof_info — Sets the corresponding bit in the enable register when set. Write only, self-clears.
  [2] si_egr_iq_efe_sym_err — Sets the corresponding bit in the enable register when set. Write only, self-clears.
  [1] si_egr_iq_efe_pkt_err — Sets the corresponding bit in the enable register when set. Write only, self-clears.
  [0] si_egr_iq_efe_starve_err — Sets the corresponding bit in the enable register when set. Write only, self-clears.
0x101CC AID2_ee_sie_a_EV0_Enable_Clear wo — (1 of 1, stride 0)
  [4] si_egr_iq_icc_dat_info — Clears the corresponding bit in the enable register when set. Write only, self-clears.
  [3] si_egr_iq_icc_sof_info — Clears the corresponding bit in the enable register when set. Write only, self-clears.
  [2] si_egr_iq_efe_sym_err — Clears the corresponding bit in the enable register when set. Write only, self-clears.
  [1] si_egr_iq_efe_pkt_err — Clears the corresponding bit in the enable register when set. Write only, self-clears.
  [0] si_egr_iq_efe_starve_err — Clears the corresponding bit in the enable register when set. Write only, self-clears.
